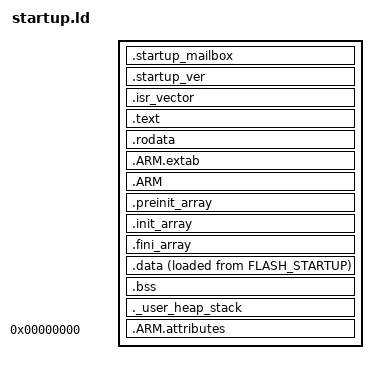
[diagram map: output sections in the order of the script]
/**
 * @file       startup.ld
 * @brief      Linker script for building Start-up code
 * @author     Mike Tolkachev <contact@miketolkachev.dev>
 * @copyright  Copyright 2020 Crypto Advance GmbH. All rights reserved.
 */

/* Default entry point (redefined in debug build) */
ENTRY(startup_entry)

/* Generate a link error if heap and stack don't fit into RAM */
_min_heap_size  = 4K;  /* required amount of heap  */
_min_stack_size = 32K;  /* required amount of stack */

SECTIONS
{
  /* Mailbox used by the Start-up code to pass parameters to the Bootloader */
  .startup_mailbox :
  {
    . = ALIGN(4);
    *(.startup_mailbox.*)
  } >RAM_MAILBOX

  .startup_ver :
  {
    . = ALIGN(4);
    *(.startup_ver.*)
  } >FLASH_STARTUP_VER

  /* Main startup code in RAM */
  .isr_vector :
  {
    . = ALIGN(4);
    _bootloader_start = .;
    KEEP(*(.isr_vector)) /* Startup code */
    . = ALIGN(4);
  } >FLASH_STARTUP

  /* The program code and other data goes into RAM */
  .text :
  {
    . = ALIGN(4);
    *(.text)           /* .text sections (code) */
    *(.text*)          /* .text* sections (code) */
    *(.glue_7)         /* glue arm to thumb code */
    *(.glue_7t)        /* glue thumb to arm code */
    *(.eh_frame)

    KEEP (*(.init))
    KEEP (*(.fini))

    . = ALIGN(4);
    _etext = .;        /* define a global symbols at end of code */
  } >FLASH_STARTUP

  /* Constant data goes into RAM */
  .rodata :
  {
    . = ALIGN(4);
    *(.rodata)         /* .rodata sections (constants, strings, etc.) */
    *(.rodata*)        /* .rodata* sections (constants, strings, etc.) */
    . = ALIGN(4);
  } >FLASH_STARTUP

  .ARM.extab   : { *(.ARM.extab* .gnu.linkonce.armextab.*) } >RAM
  .ARM : {
    __exidx_start = .;
    *(.ARM.exidx*)
    __exidx_end = .;
  } >FLASH_STARTUP

  .preinit_array     :
  {
    PROVIDE_HIDDEN (__preinit_array_start = .);
    KEEP (*(.preinit_array*))
    PROVIDE_HIDDEN (__preinit_array_end = .);
  } >FLASH_STARTUP
  .init_array :
  {
    PROVIDE_HIDDEN (__init_array_start = .);
    KEEP (*(SORT(.init_array.*)))
    KEEP (*(.init_array*))
    PROVIDE_HIDDEN (__init_array_end = .);
  } >FLASH_STARTUP
  .fini_array :
  {
    PROVIDE_HIDDEN (__fini_array_start = .);
    KEEP (*(SORT(.fini_array.*)))
    KEEP (*(.fini_array*))
    PROVIDE_HIDDEN (__fini_array_end = .);
  } >FLASH_STARTUP

  /* Initialized data sections goes into RAM, load LMA copy after code */
  .data :
  {
    . = ALIGN(4);
    *(.data)           /* .data sections */
    *(.data*)          /* .data* sections */
    . = ALIGN(4);
  } >RAM AT>FLASH_STARTUP

  /* Uninitialized data section */
  . = ALIGN(4);
  .bss :
  {
    /* This is used by the startup in order to initialize the .bss secion */
    _sbss = .;         /* define a global symbol at bss start */
    __bss_start__ = _sbss;
    *(.bss)
    *(.bss*)
    *(COMMON)
    . = ALIGN(4);
    _ebss = .;         /* define a global symbol at bss end */
    __bss_end__ = _ebss;
  } >RAM

  /* User_heap_stack section, used to check that there is enough RAM left */
  ._user_heap_stack :
  {
    . = ALIGN(4);
    PROVIDE ( end = . );
    PROVIDE ( _end = . );
    . = . + _min_heap_size;
    . = . + _min_stack_size;
    . = ALIGN(4);
  } >RAM

  /* Remove information from the standard libraries */
  /DISCARD/ :
  {
    libc.a ( * )
    libm.a ( * )
    libgcc.a ( * )
  }

  .ARM.attributes 0 : { *(.ARM.attributes) }
}


